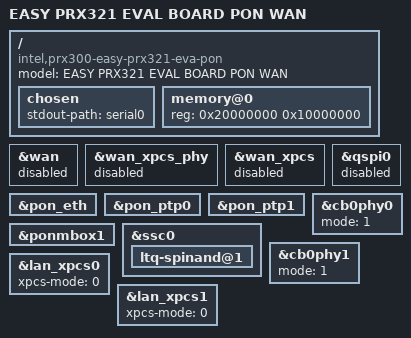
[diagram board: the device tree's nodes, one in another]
/dts-v1/;
#include <dt-bindings/interrupt-controller/mips-gic.h>
#include <dt-bindings/clock/intel,falconmx-clk.h>
#include <dt-bindings/pinctrl/intel,equilibrium.h>
#include "falconmx.dtsi"
#include "prx220a_evm.dtsi"

/ {
	model = "EASY PRX321 EVAL BOARD PON WAN";
	compatible = "intel,prx300-easy-prx321-eva-pon", "intel,prx300-easy-prx321-eva", "intel,prx300", "intel,falconmx";

	chosen {
		/* bootargs = "earlycon=lantiq,0x16380000 nr_cpus=4 maxcpus=4 console=ttyLTQ0,115200 root=/dev/ram panic=1 init=/etc/preinit nocoherentio=1 clk_ignore_unused mem=94M@512M rcupdate.rcu_cpu_stall_suppress=1";*/
		stdout-path = "serial0";
	};

	memory@0 {
		device_type = "memory";
		reg = <0x20000000 0x10000000>; /* 256 MB */
	};
};

&wan {
	status = "disabled";
};

&wan_xpcs_phy {
	status = "disabled";
};

&wan_xpcs {
	status = "disabled";
};

&pon_eth {
	status = "okay";
};

&pon_ptp0 {
	status = "okay";
};

&pon_ptp1 {
	status = "okay";
};

&ponmbox1 {
	status = "okay";
};

/* temporary disable qspi nand during bringup due to board issue,
   we use spi nand as fallback option */
&ssc0 {
	status = "okay";
	ltq-spinand@1 {
		status = "okay";
	};
};

&qspi0 {
	status = "disabled";
};

&cb0phy0 {
	mode = <1>; /*0-pcie, 1-xpcs*/
	status = "okay";
};

&cb0phy1 {
	mode = <1>; /*0-pcie, 1-xpcs*/
	status = "okay";
};

&lan_xpcs0 {
	xpcs-mode = <0>; /* 0 - 10G_KR_MODE, 1 - 10G_XAUI_MODE, 2 - 1G_XAUI_MODE, 3 - 2P5G_GMII_MODE */
};

&lan_xpcs1 {
	xpcs-mode = <0>; /* 0 - 10G_KR_MODE, 1 - 10G_XAUI_MODE, 2 - 1G_XAUI_MODE, 3 - 2P5G_GMII_MODE */
};
